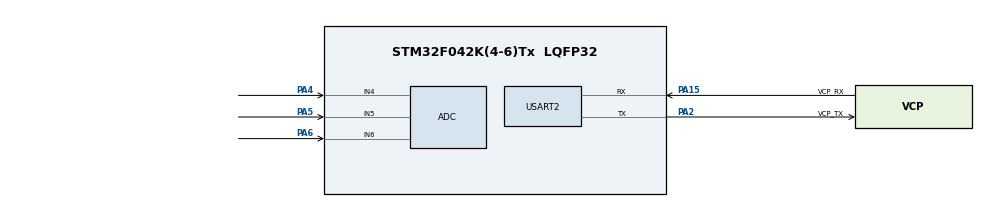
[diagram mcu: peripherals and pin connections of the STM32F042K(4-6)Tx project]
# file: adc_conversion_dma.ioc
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ADC.ContinuousConvMode=DISABLE
ADC.DMAContinuousRequests=ENABLE
ADC.DiscontinuousConvMode=ENABLE
ADC.EOCSelection=ADC_EOC_SINGLE_CONV
Dma.ADC.0.Direction=DMA_PERIPH_TO_MEMORY
Dma.ADC.0.Instance=DMA1_Channel1
Dma.ADC.0.MemDataAlignment=DMA_MDATAALIGN_HALFWORD
Dma.ADC.0.MemInc=DMA_MINC_ENABLE
Dma.ADC.0.Mode=DMA_CIRCULAR
Dma.ADC.0.PeriphDataAlignment=DMA_PDATAALIGN_HALFWORD
Dma.ADC.0.PeriphInc=DMA_PINC_DISABLE
Dma.ADC.0.Priority=DMA_PRIORITY_LOW
Dma.Request0=ADC
Mcu.Family=STM32F0
Mcu.Name=STM32F042K(4-6)Tx
Mcu.Package=LQFP32
NVIC.DMA1_Channel1_IRQn=true\:0\:0\:false\:false\:true\:false\:true\:true
PA13.GPIO_Label=SWDIO
PA13.Mode=Serial_Wire
PA13.Signal=SYS_SWDIO
PA14.GPIO_Label=SWCLK
PA14.Mode=Serial_Wire
PA14.Signal=SYS_SWCLK
PA15.GPIO_Label=VCP_RX
PA15.Mode=Asynchronous
PA15.Signal=USART2_RX
PA2.GPIO_Label=VCP_TX
PA2.Mode=Asynchronous
PA2.Signal=USART2_TX
PA4.Mode=IN4
PA4.Signal=ADC_IN4
PA5.Mode=IN5
PA5.Signal=ADC_IN5
PA6.Mode=IN6
PA6.Signal=ADC_IN6
PF0-OSC_IN.GPIO_Label=MCO
PF0-OSC_IN.Mode=HSE-External-Clock-Source
PF0-OSC_IN.Signal=RCC_OSC_IN
ProjectManager.HeapSize=0x200
ProjectManager.StackSize=0x400
ProjectManager.TargetToolchain=STM32CubeIDE
USART2.VirtualMode-Asynchronous=VM_ASYNC
board=NUCLEO-F042K6

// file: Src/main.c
/* USER CODE BEGIN Header */
/**
  ******************************************************************************
  * @file           : main.c
  * @brief          : Main program body
  ******************************************************************************
  * @attention
  *
  * Copyright (c) 2022 STMicroelectronics.
  * All rights reserved.
  *
  * This software is licensed under terms that can be found in the LICENSE file
  * in the root directory of this software component.
  * If no LICENSE file comes with this software, it is provided AS-IS.
  *
  ******************************************************************************
  */
/* USER CODE END Header */
#include "main.h"

ADC_HandleTypeDef hadc;
DMA_HandleTypeDef hdma_adc;

UART_HandleTypeDef huart2;

void SystemClock_Config(void);
static void MX_GPIO_Init(void);
static void MX_DMA_Init(void);
static void MX_ADC_Init(void);
static void MX_USART2_UART_Init(void);

/* USER CODE BEGIN 0 */

int _write(int file, char *ptr, int len)
{
	HAL_UART_Transmit( &huart2, (uint8_t*)ptr, len, HAL_MAX_DELAY );
	return len;
}

/* USER CODE END 0 */

int main(void)
{

  /* MCU Configuration--------------------------------------------------------*/

  /* Reset of all peripherals, Initializes the Flash interface and the Systick. */
  HAL_Init();

  /* Configure the system clock */
  SystemClock_Config();

  /* Initialize all configured peripherals */
  MX_GPIO_Init();
  MX_DMA_Init();
  MX_ADC_Init();
  MX_USART2_UART_Init();
  /* USER CODE BEGIN 2 */
  HAL_ADCEx_Calibration_Start(&hadc);
  /* USER CODE END 2 */

  /* Infinite loop */
  /* USER CODE BEGIN WHILE */
  while (1)
  {
	  // get raw data from sensors
	  HAL_ADC_Start(&hadc);
	  HAL_ADC_PollForConversion(&hadc, HAL_MAX_DELAY);
	  int lightsens = HAL_ADC_GetValue(&hadc);

	  HAL_ADC_Start(&hadc);
	  HAL_ADC_PollForConversion(&hadc, HAL_MAX_DELAY);
	  int moistsens = HAL_ADC_GetValue(&hadc);
	  //convert values to readable ones
	  float truelightsens = ((lightsens-700)*100)/1000;
	  float truemoistsens = (moistsens*100)/4096;
	  //print values
	  printf("LIGSEN%f;", truelightsens);

	  printf("MOISEN%f;", truemoistsens);

    /* USER CODE END WHILE */

  }
}

void SystemClock_Config(void)
{
  RCC_OscInitTypeDef RCC_OscInitStruct = {0};
  RCC_ClkInitTypeDef RCC_ClkInitStruct = {0};

  /** Initializes the RCC Oscillators according to the specified parameters
  * in the RCC_OscInitTypeDef structure.
  */
  RCC_OscInitStruct.OscillatorType = RCC_OSCILLATORTYPE_HSI|RCC_OSCILLATORTYPE_HSI14;
  RCC_OscInitStruct.HSIState = RCC_HSI_ON;
  RCC_OscInitStruct.HSI14State = RCC_HSI14_ON;
  RCC_OscInitStruct.HSICalibrationValue = RCC_HSICALIBRATION_DEFAULT;
  RCC_OscInitStruct.HSI14CalibrationValue = 16;
  RCC_OscInitStruct.PLL.PLLState = RCC_PLL_NONE;
  if (HAL_RCC_OscConfig(&RCC_OscInitStruct) != HAL_OK)
  {
    Error_Handler();
  }

  /** Initializes the CPU, AHB and APB buses clocks
  */
  RCC_ClkInitStruct.ClockType = RCC_CLOCKTYPE_HCLK|RCC_CLOCKTYPE_SYSCLK
                              |RCC_CLOCKTYPE_PCLK1;
  RCC_ClkInitStruct.SYSCLKSource = RCC_SYSCLKSOURCE_HSI;
  RCC_ClkInitStruct.AHBCLKDivider = RCC_SYSCLK_DIV1;
  RCC_ClkInitStruct.APB1CLKDivider = RCC_HCLK_DIV1;

  if (HAL_RCC_ClockConfig(&RCC_ClkInitStruct, FLASH_LATENCY_0) != HAL_OK)
  {
    Error_Handler();
  }
}

static void MX_ADC_Init(void)
{

  ADC_ChannelConfTypeDef sConfig = {0};

  /** Configure the global features of the ADC (Clock, Resolution, Data Alignment and number of conversion)
  */
  hadc.Instance = ADC1;
  hadc.Init.ClockPrescaler = ADC_CLOCK_ASYNC_DIV1;
  hadc.Init.Resolution = ADC_RESOLUTION_12B;
  hadc.Init.DataAlign = ADC_DATAALIGN_RIGHT;
  hadc.Init.ScanConvMode = ADC_SCAN_DIRECTION_FORWARD;
  hadc.Init.EOCSelection = ADC_EOC_SINGLE_CONV;
  hadc.Init.LowPowerAutoWait = DISABLE;
  hadc.Init.LowPowerAutoPowerOff = DISABLE;
  hadc.Init.ContinuousConvMode = DISABLE;
  hadc.Init.DiscontinuousConvMode = ENABLE;
  hadc.Init.ExternalTrigConv = ADC_SOFTWARE_START;
  hadc.Init.ExternalTrigConvEdge = ADC_EXTERNALTRIGCONVEDGE_NONE;
  hadc.Init.DMAContinuousRequests = DISABLE;
  hadc.Init.Overrun = ADC_OVR_DATA_PRESERVED;
  if (HAL_ADC_Init(&hadc) != HAL_OK)
  {
    Error_Handler();
  }

  /** Configure for the selected ADC regular channel to be converted.
  */
  sConfig.Channel = ADC_CHANNEL_4;
  sConfig.Rank = ADC_RANK_CHANNEL_NUMBER;
  sConfig.SamplingTime = ADC_SAMPLETIME_1CYCLE_5;
  if (HAL_ADC_ConfigChannel(&hadc, &sConfig) != HAL_OK)
  {
    Error_Handler();
  }

  /** Configure for the selected ADC regular channel to be converted.
  */
  sConfig.Channel = ADC_CHANNEL_5;
  if (HAL_ADC_ConfigChannel(&hadc, &sConfig) != HAL_OK)
  {
    Error_Handler();
  }

}

static void MX_USART2_UART_Init(void)
{

  huart2.Instance = USART2;
  huart2.Init.BaudRate = 38400;
  huart2.Init.WordLength = UART_WORDLENGTH_8B;
  huart2.Init.StopBits = UART_STOPBITS_1;
  huart2.Init.Parity = UART_PARITY_NONE;
  huart2.Init.Mode = UART_MODE_TX_RX;
  huart2.Init.HwFlowCtl = UART_HWCONTROL_NONE;
  huart2.Init.OverSampling = UART_OVERSAMPLING_16;
  huart2.Init.OneBitSampling = UART_ONE_BIT_SAMPLE_DISABLE;
  huart2.AdvancedInit.AdvFeatureInit = UART_ADVFEATURE_NO_INIT;
  if (HAL_UART_Init(&huart2) != HAL_OK)
  {
    Error_Handler();
  }

}

static void MX_DMA_Init(void)
{

  /* DMA controller clock enable */
  __HAL_RCC_DMA1_CLK_ENABLE();

  /* DMA interrupt init */
  /* DMA1_Channel1_IRQn interrupt configuration */
  HAL_NVIC_SetPriority(DMA1_Channel1_IRQn, 0, 0);
  HAL_NVIC_EnableIRQ(DMA1_Channel1_IRQn);

}

static void MX_GPIO_Init(void)
{

  /* GPIO Ports Clock Enable */
  __HAL_RCC_GPIOF_CLK_ENABLE();
  __HAL_RCC_GPIOA_CLK_ENABLE();

}

void Error_Handler(void)
{
  __disable_irq();
  while (1)
  {
  }
}
